AUTOSAR XML (schema 4.0)
package /Powertrain_Components
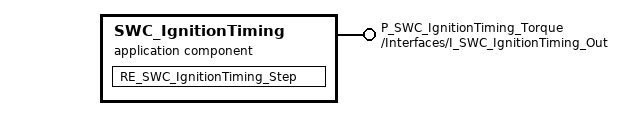
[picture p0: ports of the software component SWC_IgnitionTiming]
  application sw component type SWC_IgnitionTiming  # AUTOSAR Application SWC SWC_IgnitionTiming for Powertrain Control
    provide port P_SWC_IgnitionTiming_Torque: provided-interface=/Interfaces/I_SWC_IgnitionTiming_Out
    behavior SWC_IgnitionTiming_Behavior
      runnable RE_SWC_IgnitionTiming_Step: symbol=SWC_IgnitionTiming_Step
  sender receiver interface I_SWC_IgnitionTiming_Out
    data DE_SWC_IgnitionTiming_TorqueDemand: type=/AUTOSAR/Platform/uint32
